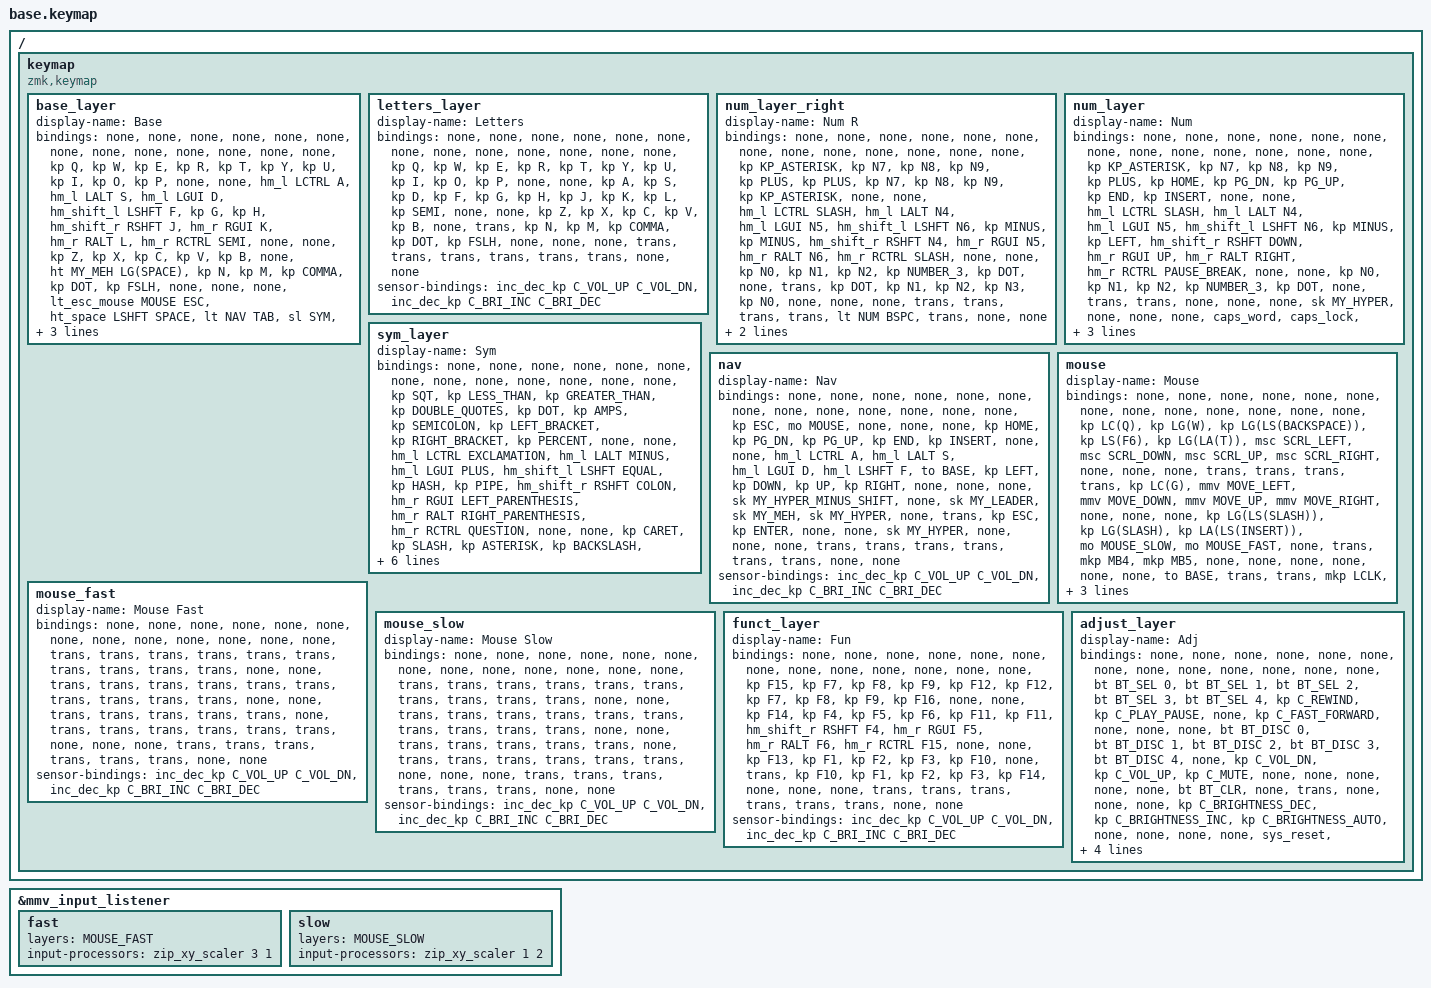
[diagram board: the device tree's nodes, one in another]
/*
* Copyright (c) 2020 The ZMK Contributors
*
* SPDX-License-Identifier: MIT
*/

// Useful web keymap editor
// https://nickcoutsos.github.io/keymap-editor/

#include "includes/layers_definitions.dtsi"
// #define MOUSE_KEYS 12
// #define MOUSE_TP 13
// #define MOUSE_TP_SET 14

// ZMK includes
#include <behaviors.dtsi>
#include <dt-bindings/zmk/keys.h>
#include <dt-bindings/zmk/bt.h>
#include <dt-bindings/zmk/ext_power.h>
#include <dt-bindings/input/input-event-codes.h>
#include <input/processors.dtsi>

// #ifdef HAS_MOUSE_KEYS
// #include <dt-bindings/zmk/mouse.h>
// #endif

#define ZMK_POINTING_DEFAULT_MOVE_VAL 1200// default: 600
#define ZMK_POINTING_DEFAULT_SCRL_VAL 20// default: 10
#include <dt-bindings/zmk/pointing.h>

#include "zmk-helpers/helper.h"
#include "zmk-helpers/unicode-chars/currency.dtsi"

// Personal includes
#include "includes/custom_keycodes.dtsi"
#include "includes/settings.dtsi"
#include "includes/conditional_layers.dtsi"
#include "includes/macros.dtsi"
#include "includes/combos.dtsi"
#include "includes/behaviours_homerow_mods.dtsi"
#include "includes/behaviours_mod_morph.dtsi"
#include "includes/layers_callbacks.dtsi"
#include "includes/behaviours_other.dtsi"

// Enable Mouse Keys
// #ifdef HAS_MOUSE_KEYS
// #include "includes/mouse_keys.dtsi"
// #endif

/*                                      60 KEY MATRIX / LAYOUT MAPPING

╭────────────────────────────┬────────────────────────────╮ ╭─────────────────────────────┬─────────────────────────────╮
│  0   1   2   3   4   5     │      6   7   8   9  10  11 │ │ LN5 LN4 LN3 LN2 LN1 LN0     │     RN0 RN1 RN2 RN3 RN4 RN5 │
│ 12  13  14  15  16  17     │     18  19  20  21  22  23 │ │ LT5 LT4 LT3 LT2 LT1 LT0     │     RT0 RT1 RT2 RT3 RT4 RT5 │
│ 24  25  26  27  28  29     │     30  31  32  33  34  35 │ │ LM5 LM4 LM3 LM2 LM1 LM0     │     RM0 RM1 RM2 RM3 RM4 RM5 │
│ 36  37  38  39  40  41  42 │ 43  44  45  46  47  48  49 │ │ LB5 LB4 LB3 LB2 LB1 LB0 LEC │ REC RB0 RB1 RB2 RB3 RB4 RB5 │
╰───────╮ 50  51  52  53  54 │ 55  56  57  58  59 ╭───────╯ ╰───────╮ LH4 LH3 LH2 LH1 LH0 │ RH0 RH1 RH2 RH3 RH4 ╭───────╯
........╰────────────────────┴────────────────────╯                 ╰─────────────────────┴─────────────────────╯
*/

/ {
	keymap {
		compatible = "zmk,keymap";
		
		base_layer {
			display-name = "Base";
			bindings = <
			&none   &none          &none          &none                    &none                &none                                                                     &none     &none                 &none          &none         &none             &none
			&none   &kp Q          &kp W          &kp E                    &kp R                &kp T                                                                     &kp Y     &kp U                 &kp I          &kp O         &kp P             &none
			&none   &hm_l LCTRL A  &hm_l LALT S   &hm_l LGUI D             &hm_shift_l LSHFT F  &kp G                                                                     &kp H     &hm_shift_r RSHFT J   &hm_r RGUI K   &hm_r RALT L  &hm_r RCTRL SEMI  &none
			&none   &kp Z          &kp X          &kp C                    &kp V                &kp B        &none                                 &ht MY_MEH LG(SPACE)   &kp N     &kp M                 &kp COMMA      &kp DOT       &kp FSLH          &none
			                       &none          &none                    &lt_esc_mouse MOUSE ESC  &ht_space LSHFT SPACE  &lt NAV TAB                          &sl SYM   &lt NUM BSPC          &lt FUNCT DEL  &none         &none
			>;
			sensor-bindings = <&inc_dec_kp C_VOL_UP C_VOL_DN  &inc_dec_kp C_VOL_UP C_VOL_DN>;
		};

		letters_layer {
			display-name = "Letters";
			bindings = <
			&none   &none   &none   &none   &none   &none                                                &none   &none   &none      &none    &none     &none
			&none   &kp Q   &kp W   &kp E   &kp R   &kp T                                                &kp Y   &kp U   &kp I      &kp O    &kp P     &none
			&none   &kp A   &kp S   &kp D   &kp F   &kp G                                                &kp H   &kp J   &kp K      &kp L    &kp SEMI  &none
			&none   &kp Z   &kp X   &kp C   &kp V   &kp B   &none                                &trans  &kp N   &kp M   &kp COMMA  &kp DOT  &kp FSLH  &none
			                &none   &none   &trans  &trans  &trans                               &trans  &trans  &trans  &none      &none
			>;
			sensor-bindings = <&inc_dec_kp C_VOL_UP C_VOL_DN  &inc_dec_kp C_BRI_INC C_BRI_DEC>;
		};
		
		num_layer_right {
			display-name = "Num R";
			bindings = <
			&none   &none              &none          &none          &none                 &none                                                   &none      &none                 &none          &none          &none              &none
			&none   &kp KP_ASTERISK    &kp N7         &kp N8         &kp N9                &kp PLUS                                                &kp PLUS   &kp N7                &kp N8         &kp N9         &kp KP_ASTERISK    &none
			&none   &hm_l LCTRL SLASH  &hm_l LALT N4  &hm_l LGUI N5  &hm_shift_l LSHFT N6  &kp MINUS                                               &kp MINUS  &hm_shift_r RSHFT N4  &hm_r RGUI N5  &hm_r RALT N6  &hm_r RCTRL SLASH  &none
			&none   &kp N0             &kp N1         &kp N2         &kp NUMBER_3          &kp DOT    &none                                &trans  &kp DOT    &kp N1                &kp N2         &kp N3         &kp N0             &none
			                           &none          &none          &trans                &trans     &trans                               &trans  &lt NUM BSPC  &trans             &none          &none
			>;
			
			sensor-bindings = <&inc_dec_kp C_VOL_UP C_VOL_DN  &inc_dec_kp C_BRI_INC C_BRI_DEC>;
		};

		num_layer {
			display-name = "Num";
			bindings = <
			&none   &none              &none          &none          &none                 &none                                                   &none     &none                   &none          &none            &none                    &none
			&none   &kp KP_ASTERISK    &kp N7         &kp N8         &kp N9                &kp PLUS                                                &kp HOME  &kp PG_DN               &kp PG_UP      &kp END          &kp INSERT               &none
			&none   &hm_l LCTRL SLASH  &hm_l LALT N4  &hm_l LGUI N5  &hm_shift_l LSHFT N6  &kp MINUS                                               &kp LEFT  &hm_shift_r RSHFT DOWN  &hm_r RGUI UP  &hm_r RALT RIGHT &hm_r RCTRL PAUSE_BREAK  &none
			&none   &kp N0             &kp N1         &kp N2         &kp NUMBER_3          &kp DOT    &none                                &trans  &trans    &none                   &none          &none            &sk MY_HYPER             &none
			                           &none          &none          &caps_word            &caps_lock &trans                               &trans  &trans    &trans                  &none          &none
			>;
			
			sensor-bindings = <&inc_dec_kp C_VOL_UP C_VOL_DN  &inc_dec_kp C_BRI_INC C_BRI_DEC>;
		};
		
		sym_layer {
			display-name = "Sym";
			bindings = <
			&none   &none                    &none            &none             &none                    &none                                                   &none      &none                      &none                        &none                         &none                 &none
			&none   &kp SQT                  &kp LESS_THAN    &kp GREATER_THAN  &kp DOUBLE_QUOTES        &kp DOT                                                 &kp AMPS   &kp SEMICOLON              &kp LEFT_BRACKET             &kp RIGHT_BRACKET             &kp PERCENT           &none
			&none   &hm_l LCTRL EXCLAMATION  &hm_l LALT MINUS &hm_l LGUI PLUS   &hm_shift_l LSHFT EQUAL  &kp HASH                                                &kp PIPE   &hm_shift_r RSHFT COLON    &hm_r RGUI LEFT_PARENTHESIS  &hm_r RALT RIGHT_PARENTHESIS  &hm_r RCTRL QUESTION  &none
			&none   &kp CARET                &kp SLASH        &kp ASTERISK      &kp BACKSLASH            &kp GRAVE  &none                                &trans  &kp TILDE  &kp DOLLAR                 &kp LEFT_BRACE               &kp RIGHT_BRACE               &kp AT_SIGN           &none
			                                 &none            &none             &kp ESC                  &to BASE   &trans                               &trans  &trans     &trans                     &none                        &none
			>;
			
			sensor-bindings = <&inc_dec_kp C_VOL_UP C_VOL_DN  &inc_dec_kp C_BRI_INC C_BRI_DEC>;
		};
		
		nav {
			display-name = "Nav";
			bindings = <
			&none   &none                     &none         &none          &none          &none                                                      &none     &none      &none      &none      &none         &none
			&none   &kp ESC                   &mo MOUSE     &none          &none          &none                                                      &kp HOME  &kp PG_DN  &kp PG_UP  &kp END    &kp INSERT    &none
			&none   &hm_l LCTRL A             &hm_l LALT S  &hm_l LGUI D   &hm_l LSHFT F  &to BASE                                                   &kp LEFT  &kp DOWN   &kp UP     &kp RIGHT  &none         &none
			&none   &sk MY_HYPER_MINUS_SHIFT  &none         &sk MY_LEADER  &sk MY_MEH     &sk MY_HYPER  &none                                &trans  &kp ESC   &kp ENTER  &none      &none      &sk MY_HYPER  &none
			                                  &none         &none          &trans         &trans        &trans                               &trans  &trans    &trans     &none      &none
			>;
			
			sensor-bindings = <&inc_dec_kp C_VOL_UP C_VOL_DN  &inc_dec_kp C_BRI_INC C_BRI_DEC>;
		};

		mouse {
			display-name = "Mouse";
			bindings = <
			&none   &none              &none          &none                  &none           &none                                                        &none           &none           &none         &none            &none  &none
			&none   &kp LC(Q)          &kp LG(W)      &kp LG(LS(BACKSPACE))  &kp LS(F6)      &kp LG(LA(T))                                                &msc SCRL_LEFT  &msc SCRL_DOWN  &msc SCRL_UP  &msc SCRL_RIGHT  &none  &none
			&none   &trans             &trans         &trans                 &trans          &kp LC(G)                                                    &mmv MOVE_LEFT  &mmv MOVE_DOWN  &mmv MOVE_UP  &mmv MOVE_RIGHT  &none  &none
			&none   &kp LG(LS(SLASH))  &kp LG(SLASH)  &kp LA(LS(INSERT))     &mo MOUSE_SLOW  &mo MOUSE_FAST  &none                                &trans  &mkp MB4        &mkp MB5        &none         &none            &none  &none
			                           &none          &none                  &to BASE        &trans          &trans                            &mkp LCLK  &mkp RCLK       &mkp MCLK       &none         &none
			>;
			
			sensor-bindings = <&inc_dec_kp C_VOL_UP C_VOL_DN  &inc_dec_kp C_BRI_INC C_BRI_DEC>;
		};
		
		mouse_fast {
			display-name = "Mouse Fast";
			bindings = <
			&none   &none   &none   &none   &none   &none                                                &none   &none   &none   &none   &none   &none
			&none   &trans  &trans  &trans  &trans  &trans                                               &trans  &trans  &trans  &trans  &trans  &none
			&none   &trans  &trans  &trans  &trans  &trans                                               &trans  &trans  &trans  &trans  &trans  &none
			&none   &trans  &trans  &trans  &trans  &trans  &none                                &trans  &trans  &trans  &trans  &trans  &trans  &none
			                &none   &none   &trans  &trans  &trans                               &trans  &trans  &trans  &none   &none
			>;
			
			sensor-bindings = <&inc_dec_kp C_VOL_UP C_VOL_DN  &inc_dec_kp C_BRI_INC C_BRI_DEC>;
		};

		mouse_slow {
			display-name = "Mouse Slow";
			bindings = <
			&none   &none   &none   &none   &none   &none                                                &none   &none   &none   &none   &none   &none
			&none   &trans  &trans  &trans  &trans  &trans                                               &trans  &trans  &trans  &trans  &trans  &none
			&none   &trans  &trans  &trans  &trans  &trans                                               &trans  &trans  &trans  &trans  &trans  &none
			&none   &trans  &trans  &trans  &trans  &trans  &none                                &trans  &trans  &trans  &trans  &trans  &trans  &none
			                &none   &none   &trans  &trans  &trans                               &trans  &trans  &trans  &none   &none
			>;
			
			sensor-bindings = <&inc_dec_kp C_VOL_UP C_VOL_DN  &inc_dec_kp C_BRI_INC C_BRI_DEC>;
		};
		
		funct_layer {
			display-name = "Fun";
			bindings = <
			&none   &none    &none   &none   &none   &none                                                 &none    &none                 &none          &none          &none            &none
			&none   &kp F15  &kp F7  &kp F8  &kp F9  &kp F12                                               &kp F12  &kp F7                &kp F8         &kp F9         &kp F16          &none
			&none   &kp F14  &kp F4  &kp F5  &kp F6  &kp F11                                               &kp F11  &hm_shift_r RSHFT F4  &hm_r RGUI F5  &hm_r RALT F6  &hm_r RCTRL F15  &none
			&none   &kp F13  &kp F1  &kp F2  &kp F3  &kp F10  &none                                &trans  &kp F10  &kp F1                &kp F2         &kp F3         &kp F14          &none
			                 &none   &none   &trans  &trans   &trans                               &trans  &trans   &trans                &none          &none
			>;
			
			sensor-bindings = <&inc_dec_kp C_VOL_UP C_VOL_DN  &inc_dec_kp C_BRI_INC C_BRI_DEC>;
		};
		
		adjust_layer {
			display-name = "Adj";
			bindings = <
			&none   &none          &none          &none          &none          &none                                                       &none          &none                  &none                  &none                   &none  &none
			&none   &bt BT_SEL 0   &bt BT_SEL 1   &bt BT_SEL 2   &bt BT_SEL 3   &bt BT_SEL 4                                                &kp C_REWIND   &kp C_PLAY_PAUSE       &none                  &kp C_FAST_FORWARD      &none  &none
			&none   &bt BT_DISC 0  &bt BT_DISC 1  &bt BT_DISC 2  &bt BT_DISC 3  &bt BT_DISC 4                                               &none          &kp C_VOL_DN           &kp C_VOL_UP           &kp C_MUTE              &none  &none
			&none   &none          &none          &bt BT_CLR     &none          &trans         &none                                 &none  &none          &kp C_BRIGHTNESS_DEC   &kp C_BRIGHTNESS_INC   &kp C_BRIGHTNESS_AUTO   &none  &none
			                       &none          &none          &sys_reset     &bootloader    &trans                               &trans  &bootloader    &sys_reset             &none                  &none
			>;
			
			sensor-bindings = <&inc_dec_kp C_VOL_UP C_VOL_DN  &inc_dec_kp C_BRI_INC C_BRI_DEC>;
		};
		
	};
};

&mmv_input_listener {
	fast {
		layers = <MOUSE_FAST>;
		input-processors = <&zip_xy_scaler 3 1>;
	};
	slow {
		layers = <MOUSE_SLOW>;
		input-processors = <&zip_xy_scaler 1 2>;
	};
};
